# STM32MP13xx register map
File version: 1.5
CPU: CA7 r0p0, little endian, MPU, FPU, 4 interrupt priority bits
Registers are 32-bit, read-write, reset 0x0 unless marked. A register's access mark holds for its fields unless they carry their own. Offsets are from the block's base; [hi:lo] are bit positions; {n}, {i} and the like mark numbered series; 'fields as' and 'values as' point back to an identical list.

## RCC (part 6 of 7)
Base 0x50000000
0x790 RCC_MP_NS_AHB6ENSETR — This is a non-secure register for enabling the clock of the MDMA when it is used as non- secure. This register is used to set the peripheral clock enable bit of the corresponding peripheral. It shall be used to allocate a peripheral. Writing '0' has no effect, reading will return the effective values of the corresponding bits. Writing a '1' sets the corresponding bit to '1'.
  [0] MDMAEN — MDMA peripheral clocks enable Set by software.
    0=Writing '0' has no effect, reading '0' means that the peripheral clocks are disabled; 1=Writing '1' enables the peripheral clocks, reading '1' means that the peripheral clocks are enabled
0x794 RCC_MP_NS_AHB6ENCLRR — This is a non-secure register for disabling the clock of the MDMA when it is not used as non- secure. This register is used to clear the peripheral clock enable bit of the corresponding peripheral. It shall be used to deallocate a peripheral. Writing '0' has no effect, reading will return the effective values of the corresponding bits. Writing a '1' sets the corresponding bit to '0'.
  fields as RCC_MP_NS_AHB6ENSETR
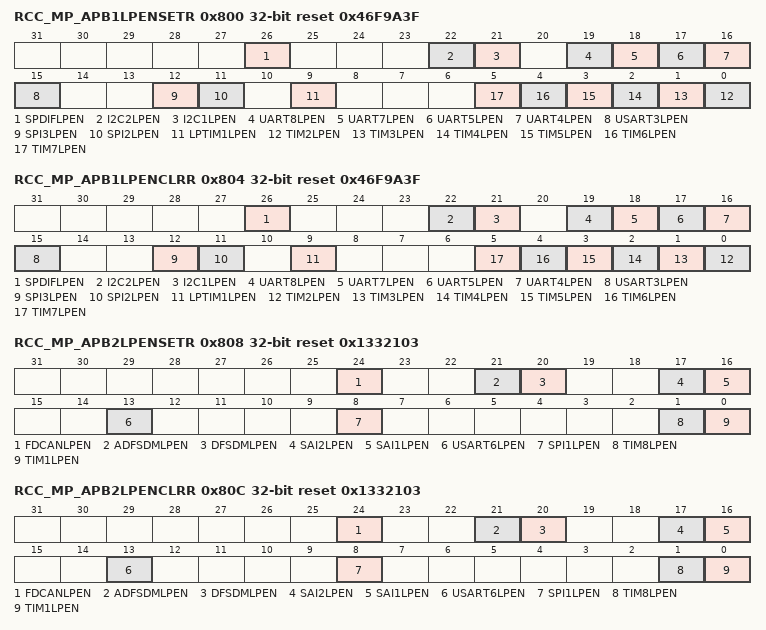
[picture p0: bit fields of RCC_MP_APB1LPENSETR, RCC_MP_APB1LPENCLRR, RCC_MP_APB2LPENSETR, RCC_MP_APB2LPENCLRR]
0x800 RCC_MP_APB1LPENSETR reset 0x46F9A3F — This register is used in order to set the PERxLPEN bit of the corresponding peripheral. Writing '0' has no effect, reading will return the effective values of the corresponding bits. Writing a '1' sets the corresponding bit to '1'.
  [all] fields
    0=Writing '0' has no effect, reading '0' means that the peripheral clocks are disabled in CSleep; 1=Writing '1' enables the peripheral clocks in CSleep, reading '1' means that the peripheral clocks are enabled in CSleep
  [26] SPDIFLPEN — SPDIFRX peripheral clocks enable during CSleep mode Set by software.
  [22] I2C2LPEN — I2C2 peripheral clocks enable during CSleep mode Set by software.
  [21] I2C1LPEN — I2C1 peripheral clocks enable during CSleep mode Set by software.
  [19] UART8LPEN — UART8 peripheral clocks enable during CSleep mode Set by software.
  [18] UART7LPEN — UART7 peripheral clocks enable during CSleep mode Set by software.
  [17] UART5LPEN — UART5 peripheral clocks enable during CSleep mode Set by software.
  [16] UART4LPEN — UART4 peripheral clocks enable during CSleep mode Set by software.
  [15] USART3LPEN — USART3 peripheral clocks enable during CSleep mode Set by software.
  [12] SPI3LPEN — SPI3 peripheral clocks enable during CSleep mode Set by software.
  [11] SPI2LPEN — SPI2 peripheral clocks enable during CSleep mode Set by software.
  [9] LPTIM1LPEN — LPTIM1 peripheral clocks enable during CSleep mode Set by software.
  [n-2] TIM{n}LPEN (n=2..7) — TIM{n} peripheral clocks enable during CSleep mode Set by software.
0x804 RCC_MP_APB1LPENCLRR reset 0x46F9A3F — This register is used in order to clear the PERxLPEN bit of the corresponding peripheral. Writing '0' has no effect, reading will return the effective values of the corresponding bits. Writing a '1' sets the corresponding bit to '0'.
  [all] fields
    0=Writing '0' has no effect, reading '0' means that the peripheral clocks are disabled in CSleep; 1=Writing '1' disables the peripheral clocks in CSleep, reading '1' means that the peripheral clocks are enabled in CSleep
  [26] SPDIFLPEN — SPDIFRX peripheral clocks enable during CSleep mode Cleared by software.
  [22] I2C2LPEN — I2C2 peripheral clocks enable during CSleep mode Cleared by software.
  [21] I2C1LPEN — I2C1 peripheral clocks enable during CSleep mode Cleared by software.
  [19] UART8LPEN — UART8 peripheral clocks enable during CSleep mode Cleared by software.
  [18] UART7LPEN — UART7 peripheral clocks enable during CSleep mode Cleared by software.
  [17] UART5LPEN — UART5 peripheral clocks enable during CSleep mode Cleared by software.
  [16] UART4LPEN — UART4 peripheral clocks enable during CSleep mode Cleared by software.
  [15] USART3LPEN — USART3 peripheral clocks enable during CSleep mode Cleared by software.
  [12] SPI3LPEN — SPI3 peripheral clocks enable during CSleep mode Cleared by software.
  [11] SPI2LPEN — SPI2 peripheral clocks enable during CSleep mode Cleared by software.
  [9] LPTIM1LPEN — LPTIM1 peripheral clocks enable during CSleep mode Cleared by software.
  [n-2] TIM{n}LPEN (n=2..7) — TIM{n} peripheral clocks enable during CSleep mode Cleared by software.
0x808 RCC_MP_APB2LPENSETR reset 0x1332103 — This register is used in order to set the PERxLPEN bit of the corresponding peripheral. Writing '0' has no effect, reading will return the effective values of the corresponding bits. Writing a '1' sets the corresponding bit to '1'.
  [all] fields
    values as the fields of RCC_MP_APB1LPENSETR
  [24] FDCANLPEN — FDCAN and CANRAM peripheral clocks enable during CSleep mode Set by software.
  [21] ADFSDMLPEN — Audio DFSDM peripheral clocks enable during CSleep mode Set by software.
  [20] DFSDMLPEN — DFSDM peripheral clocks enable during CSleep mode Set by software.
  [17] SAI2LPEN — SAI2 peripheral clocks enable during CSleep mode Set by software.
  [16] SAI1LPEN — SAI1 peripheral clocks enable during CSleep mode Set by software.
  [13] USART6LPEN — USART6 peripheral clocks enable during CSleep mode Set by software.
  [8] SPI1LPEN — SPI/I2S1 peripheral clocks enable during CSleep mode Set by software.
  [1] TIM8LPEN — TIM8 peripheral clocks enable during CSleep mode Set by software.
  [0] TIM1LPEN — TIM1 peripheral clocks enable during CSleep mode Set by software.
0x80C RCC_MP_APB2LPENCLRR reset 0x1332103 — This register is used in order to clear the PERxLPEN bit of the corresponding peripheral. Writing '0' has no effect, reading will return the effective values of the corresponding bits. Writing a '1' sets the corresponding bit to '0'.
  [all] fields
    values as the fields of RCC_MP_APB1LPENCLRR
  [24] FDCANLPEN — FDCAN and CANRAM peripheral clocks enable during CSleep mode Cleared by software.
  [21] ADFSDMLPEN — Audio DFSDM peripheral clocks enable during CSleep mode Cleared by software.
  [20] DFSDMLPEN — DFSDM peripheral clocks enable during CSleep mode Cleared by software.
  [17] SAI2LPEN — SAI2 peripheral clocks enable during CSleep mode Cleared by software.
  [16] SAI1LPEN — SAI1 peripheral clocks enable during CSleep mode Cleared by software.
  [13] USART6LPEN — USART6 peripheral clocks enable during CSleep mode Cleared by software.
  [8] SPI1LPEN — SPI/I2S1 peripheral clocks enable during CSleep mode Cleared by software.
  [1] TIM8LPEN — TIM8 peripheral clocks enable during CSleep mode Cleared by software.
  [0] TIM1LPEN — TIM1 peripheral clocks enable during CSleep mode Cleared by software.
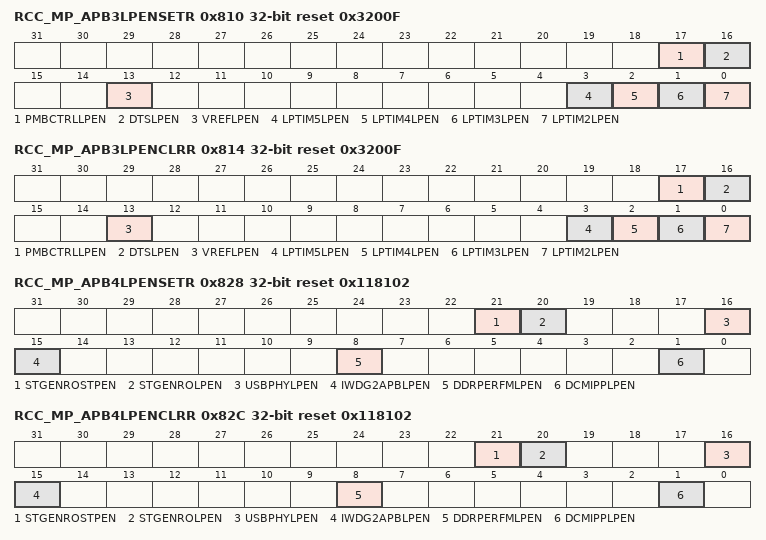
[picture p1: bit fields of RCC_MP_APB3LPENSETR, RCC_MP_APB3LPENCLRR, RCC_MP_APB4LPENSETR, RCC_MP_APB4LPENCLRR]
0x810 RCC_MP_APB3LPENSETR reset 0x3200F — This register may be separately and securely write-protected at a field level, as detailed in the following register fields description. This register is used in order to set the PERxLPEN bit of the corresponding peripheral. Writing '0' has no effect, reading will return the effective values of the corresponding bits. Writing a '1' sets the corresponding bit to '1'.
  [17] PMBCTRLLPEN — PMBCTRL peripheral clocks enable during CSeep mode (non-user): this bit is present in the RTL and is internally used as: SPIRIT parameter RTLPRESENT
  [16] DTSLPEN — DTS peripheral clocks enable during CSleep mode Set by software.
    values as the fields of RCC_MP_APB1LPENSETR
  [13] VREFLPEN — VREF peripheral clocks enable during CSleep mode If VREF block is configured as secure via the corresponding DECPROT[1] field of the ETZPC register, a write access to this register field must be secure. A read access may be secure or non-secure. Set by software.
    values as the fields of RCC_MP_APB1LPENSETR
  [3] LPTIM5LPEN — LPTIM5 peripheral clocks enable during CSleep mode Set by software.
    values as the fields of RCC_MP_APB1LPENSETR
  [2] LPTIM4LPEN — LPTIM4 peripheral clocks enable during CSleep mode Set by software.
    values as the fields of RCC_MP_APB1LPENSETR
  [1] LPTIM3LPEN — LPTIM3 peripheral clocks enable during CSleep mode If LPTIM3 block is configured as secure via the corresponding DECPROT[1] field of the ETZPC register, a write access to this register field must be secure. A read access may be secure or non-secure. Set by software.
    values as the fields of RCC_MP_APB1LPENSETR
  [0] LPTIM2LPEN — LPTIM2 peripheral clocks enable during CSleep mode If LPTIM2 block is configured as secure via the corresponding DECPROT[1] field of the ETZPC register, a write access to this register field must be secure. A read access may be secure or non-secure. Set by software.
    values as the fields of RCC_MP_APB1LPENSETR
0x814 RCC_MP_APB3LPENCLRR reset 0x3200F — This register may be separately and securely write-protected at a field level, as detailed in the following register fields description. This register is used in order to clear the PERxLPEN bit of the corresponding peripheral. Writing '0' has no effect, reading will return the effective values of the corresponding bits. Writing a '1' sets the corresponding bit to '0'.
  [17] PMBCTRLLPEN — PMBCTRL peripheral clocks enable during CSeep mode (non-user): this bit is present in the RTL and is internally used as: SPIRIT parameter RTLPRESENT
  [16] DTSLPEN — DTS peripheral clocks enable during CSleep mode Cleared by software.
    values as the fields of RCC_MP_APB1LPENCLRR
  [13] VREFLPEN — VREF peripheral clocks enable during CSleep mode If VREF block is configured as secure via the corresponding DECPROT[1] field of the ETZPC register, a write access to this register field must be secure. A read access may be secure or non-secure. Cleared by software.
    values as the fields of RCC_MP_APB1LPENCLRR
  [3] LPTIM5LPEN — LPTIM5 peripheral clocks enable during CSleep mode Cleared by software.
    values as the fields of RCC_MP_APB1LPENCLRR
  [2] LPTIM4LPEN — LPTIM4 peripheral clocks enable during CSleep mode Cleared by software.
    values as the fields of RCC_MP_APB1LPENCLRR
  [1] LPTIM3LPEN — LPTIM3 peripheral clocks enable during CSleep mode If LPTIM3 block is configured as secure via the corresponding DECPROT[1] field of the ETZPC register, a write access to this register field must be secure. A read access may be secure or non-secure. Cleared by software.
    values as the fields of RCC_MP_APB1LPENCLRR
  [0] LPTIM2LPEN — LPTIM2 peripheral clocks enable during CSleep mode If LPTIM2 block is configured as secure via the corresponding DECPROT[1] field of the ETZPC register, a write access to this register field must be secure. A read access may be secure or non-secure. Cleared by software.
    values as the fields of RCC_MP_APB1LPENCLRR
0x818 RCC_MP_S_APB3LPENSETR reset 0x1 — This is a secure register for enabling the clock of the SYSCFG. A write access to this register field must be secure. A read access may be secure or non-secure. This register is used in order to set the PERxLPEN bit of the corresponding peripheral. Writing '0' has no effect, reading will return the effective values of the corresponding bits. Writing a '1' sets the corresponding bit to '1'.
  [0] SYSCFGLPEN — SYSCFG peripheral clocks enable during CSleep mode Set by (secure) software.
    values as the fields of RCC_MP_APB1LPENSETR
0x81C RCC_MP_S_APB3LPENCLRR reset 0x1 — This is a secure register for disabling the clock of the SYSCFG. A write access to this register field must be secure. A read access may be secure or non-secure. This register is used in order to clear the PERxLPEN bit of the corresponding peripheral. Writing '0' has no effect, reading will return the effective values of the corresponding bits. Writing a '1' sets the corresponding bit to '0'.
  [0] SYSCFGLPEN — SYSCFG peripheral clocks enable during CSleep mode Cleared by (secure) software.
    values as the fields of RCC_MP_APB1LPENCLRR
0x820 RCC_MP_NS_APB3LPENSETR reset 0x1 — This is a non-secure register, for enabling the clock of the SYSCFG. This register is used in order to set the PERxLPEN bit of the corresponding peripheral. Writing '0' has no effect, reading will return the effective values of the corresponding bits. Writing a '1' sets the corresponding bit to '1'.
  [0] SYSCFGLPEN — SYSCFG peripheral clocks enable during CSleep mode Set by software.
    values as the fields of RCC_MP_APB1LPENSETR
0x824 RCC_MP_NS_APB3LPENCLRR reset 0x1 — This is a non-secure register, for disabling the clock of the SYSCFG. This register is used in order to clear the PERxLPEN bit of the corresponding peripheral. Writing '0' has no effect, reading will return the effective values of the corresponding bits. Writing a '1' sets the corresponding bit to '0'.
  [0] SYSCFGLPEN — SYSCFG peripheral clocks enable during CSleep mode Cleared by software.
    values as the fields of RCC_MP_APB1LPENCLRR
0x828 RCC_MP_APB4LPENSETR reset 0x118102 — This register may be separately and securely write-protected at a field level, as detailed in the following register fields description. This register is used in order to set the PERxLPEN bit of the corresponding peripheral. Writing '0' has no effect, reading will return the effective values of the corresponding bits. Writing a '1' sets the corresponding bit to '1'.
  [21] STGENROSTPEN — STGEN read-only interface peripheral clocks enable during CStop mode Set by software. The peripheral clocks of the STGEN read-only interface are the pclk4, and the kernel clock as selected by the RCC_STGENCKSELR register.
    0=Writing '0' has no effect, reading '0' means that the pclk4 is disabled in CStop, and that the kernel clock gating is defined by RCC_MP_APB5ENxxxR.STGENCEN with xxx=SET/CLR; 1=Writing '1' enables the pclk4 and the kernel clock in CStop; reading '1' means that the pck4 and the kernel clock are enabled in CStop
  [20] STGENROLPEN — STGEN read-only interface peripheral clocks enable during CSleep mode Set by software. The peripheral clocks of the STGEN read-only interface are the pclk4, and the kernel clock as selected by the RCC_STGENCKSELR register.
    0=Writing '0' has no effect, reading '0' means that the pclk4 is disabled in CSleep, and that the kernel clock gating is defined by RCC_MP_APB5ENxxxR.STGENCEN with xxx=SET/CLR; 1=Writing '1' enables the pclk4 and the kernel clock in CSleep; reading '1' means that the pck4 and the kernel clock are enabled in CSleep
  [16] USBPHYLPEN — USBPHYC peripheral clocks enable during CSleep mode If USB PHY is configured as secure via the corresponding DECPROT[1] field of the ETZPC register, a write access to this register field must be secure. A read access may be secure or non-secure. Set by software.
    values as the fields of RCC_MP_APB1LPENSETR
  [15] IWDG2APBLPEN — IWDG2 APB clock enable during CSleep mode Set by software.
    0=Writing '0' has no effect, reading '0' means that the APB clock is disabled in CSleep; 1=Writing '1' enables the APB clock in CSleep, reading '1' means that the APB clock is enabled in CSleep
  [8] DDRPERFMLPEN — DDRPERFM APB clock enable during CSleep mode Set by software.
    values as IWDG2APBLPEN
  [1] DCMIPPLPEN — DCMIPP peripheral clocks enable during CSleep mode If DCMIPP is configured as secure via the corresponding DECPROT[1] field of the ETZPC register, a write access to this register field must be secure. A read access may be secure or non-secure. Set by software.
    values as the fields of RCC_MP_APB1LPENSETR
0x82C RCC_MP_APB4LPENCLRR reset 0x118102 — This register may be separately and securely write-protected at a field level, as detailed in the following register fields description. This register is used in order to clear the PERxLPEN bit of the corresponding peripheral. Writing '0' has no effect, reading will return the effective values of the corresponding bits. Writing a '1' sets the corresponding bit to '0'.
  [21] STGENROSTPEN — STGEN read-only interface peripheral clocks enable during CStop mode Cleared by software. The peripheral clocks of the STGEN read-only interface are the pclk4, and the kernel clock as selected by the RCC_STGENCKSELR register.
    0=Writing '0' has no effect, reading '0' means that the pclk4 is disabled in CStop, and that the kernel clock gating is defined by RCC_MP_APB5LPENxxxR.STGENCLPEN with xxx=SET/CLR; 1=Writing '1' disables the pclk4 and the kernel clock in CStop; reading '1' means that the pck4 and the kernel clock are enabled in CStop
  [20] STGENROLPEN — STGEN read-only interface peripheral clocks enable during CSleep mode Cleared by software. The peripheral clocks of the STGEN read-only interface are the pclk4, and the kernel clock as selected by the RCC_STGENCKSELR register.
    0=Writing '0' has no effect, reading '0' means that the pclk4 is disabled in CSleep, and that the kernel clock gating is defined by RCC_MP_APB5LPENxxxR.STGENCLPEN with xxx=SET/CLR; 1=Writing '1' disables the pclk4 and the kernel clock in CSleep; reading '1' means that the pck4 and the kernel clock are enabled in CSleep
  [16] USBPHYLPEN — USBPHYC peripheral clocks enable during CSleep mode If USB PHY is configured as secure via the corresponding DECPROT[1] field of the ETZPC register, a write access to this register field must be secure. A read access may be secure or non-secure. Cleared by software.
    values as the fields of RCC_MP_APB1LPENCLRR
  [15] IWDG2APBLPEN — IWDG2 APB clock enable during CSleep mode Cleared by software.
    0=Writing '0' has no effect, reading '0' means that the APB clock is disabled in CSleep; 1=Writing '1' disables the APB clock in CSleep, reading '1' means that the APB clock is enabled in CSleep
  [8] DDRPERFMLPEN — DDRPERFM APB clock enable during CSleep mode Cleared by software.
    values as IWDG2APBLPEN
  [1] DCMIPPLPEN — DCMIPP peripheral clocks enable during CSleep mode If DCMIPP is configured as secure via the corresponding DECPROT[1] field of the ETZPC register, a write access to this register field must be secure. A read access may be secure or non-secure. Cleared by software.
    values as the fields of RCC_MP_APB1LPENCLRR
0x830 RCC_MP_S_APB4LPENSETR reset 0x1 — This is a secure register for enabling the clock of the LTDC when it is used with a secure composition layer. A write access to this register field must be secure. A read access may be secure or non-secure. This register is used in order to set the PERxLPEN bit of the corresponding peripheral. Writing '0' has no effect, reading will return the effective values of the corresponding bits. Writing a '1' sets the corresponding bit to '1'.
  [0] LTDCLPEN — LTDC peripheral clocks enable during CSleep mode Set by (secure) software.
    0=Writing '0' has no effect, reading '0' means that the peripheral clocks are disabled in CSleep; 1=Writing '1' enables the peripheral clocks in CSleep, reading '1' means that the peripheral clocks are enabled
0x834 RCC_MP_S_APB4LPENCLRR reset 0x1 — This is a secure register for disabling the clock of the LTDC when it is used with a secure composition layer. A write access to this register field must be secure. A read access may be secure or non-secure. This register is used in order to clear the PERxLPEN bit of the corresponding peripheral. Writing '0' has no effect, reading will return the effective values of the corresponding bits. Writing a '1' sets the corresponding bit to '0'.
  [0] LTDCLPEN — LTDC peripheral clocks enable during CSleep mode Cleared by (secure) software.
    0=Writing '0' has no effect, reading '0' means that the peripheral clocks are disabled in CSleep; 1=Writing '1' disables the peripheral clocks in CSleep, reading '1' means that the peripheral clocks are enabled
0x838 RCC_MP_NS_APB4LPENSETR reset 0x1 — This is a non-secure register, for enabling the clock of the LTDC when it is used with one or two non-secure composition layers. This register is used in order to set the PERxLPEN bit of the corresponding peripheral. Writing '0' has no effect, reading will return the effective values of the corresponding bits. Writing a '1' sets the corresponding bit to '1'.
  [0] LTDCLPEN — LTDC peripheral clocks enable during CSleep mode Set by software.
    values as RCC_MP_S_APB4LPENSETR.LTDCLPEN
0x83C RCC_MP_NS_APB4LPENCLRR reset 0x1 — This is a non-secure register, for disabling the clock of the LTDC when it is used with one or two non-secure composition layers. This register is used in order to clear the PERxLPEN bit of the corresponding peripheral. Writing '0' has no effect, reading will return the effective values of the corresponding bits. Writing a '1' sets the corresponding bit to '0'.
  [0] LTDCLPEN — LTDC peripheral clocks enable during CSleep mode Cleared by software.
    values as RCC_MP_S_APB4LPENCLRR.LTDCLPEN
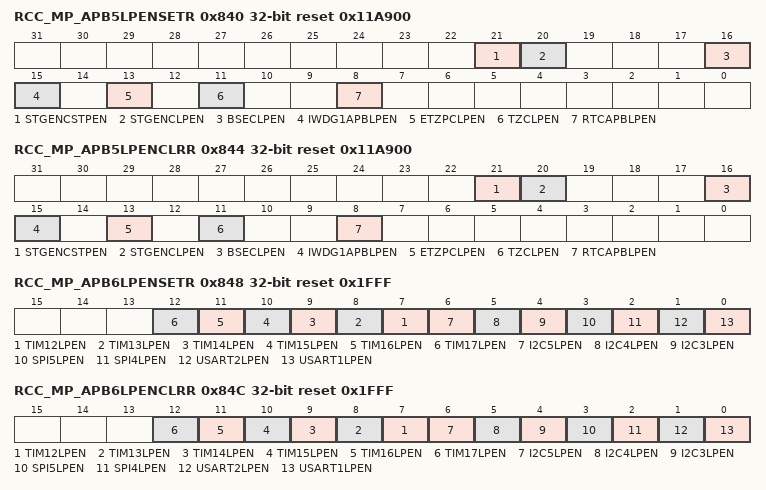
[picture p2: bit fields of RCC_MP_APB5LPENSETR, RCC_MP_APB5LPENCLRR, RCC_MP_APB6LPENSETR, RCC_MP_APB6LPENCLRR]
0x840 RCC_MP_APB5LPENSETR reset 0x11A900 — This register may be separately and securely write-protected at a field level, as detailed in the following register fields description. This register is used in order to set the PERxLPEN bit of the corresponding peripheral. Writing '0' has no effect, reading will return the effective values of the corresponding bits. Writing a '1' sets the corresponding bit to '1'.
  [21] STGENCSTPEN — STGEN controller part, peripheral clocks enable during CStop mode If STGENC is configured as secure via the corresponding DECPROT[1] field of the ETZPC register, a write access to this register field must be secure. A read access may be secure or non-secure. Set by software. The peripheral clocks of the STGEN controller part are the pclk5, and the kernel clock as selected by the RCC_STGENCKSELR register.
    0=Writing '0' has no effect, reading '0' means that the pclk5 is disabled in CStop, and that the kernel clock gating is defined by RCC_MP_APB4ENxxxR.STGENROSTPEN with xxx=SET/CLR; 1=Writing '1' enables the pclk5 and the kernel clock in CStop; reading '1' means that the pck5 and the kernel clock are enabled in CStop
  [20] STGENCLPEN — STGEN controller part, peripheral clocks enable during CSleep mode If STGENC is configured as secure via the corresponding DECPROT[1] field of the ETZPC register, a write access to this register field must be secure. A read access may be secure or non-secure. Set by software. The peripheral clocks of the STGEN controller part are the pclk5, and the kernel clock as selected by the RCC_STGENCKSELR register.
    0=Writing '0' has no effect, reading '0' means that the pclk5 is disabled in CSleep, and that the kernel clock gating is defined by RCC_MP_APB4ENxxxR.STGENROLPEN with xxx=SET/CLR; 1=Writing '1' enables the pclk5 and the kernel clock in CSleep; reading '1' means that the pck5 and the kernel clock are enabled in CSleep
  [16] BSECLPEN — BSEC peripheral clocks enable during CSleep mode A write access to this register field must be secure. A read access may be secure or non-secure. Set by (secure) software.
    values as the fields of RCC_MP_APB1LPENSETR
  [15] IWDG1APBLPEN — IWDG1 APB clock enable during CSleep mode If IWDG1 is configured as secure via the corresponding DECPROT[1] field of the ETZPC register, a write access to this register field must be secure. A read access may be secure or non-secure. Set by software.
    values as RCC_MP_APB4LPENSETR.IWDG2APBLPEN
  [13] ETZPCLPEN — ETZPC peripheral clocks enable during CSleep mode A write access to this register field must be secure. A read access may be secure or non-secure. Set by (secure) software.
    values as the fields of RCC_MP_APB1LPENSETR
  [11] TZCLPEN — TZC clocks enable during CSleep mode Set by (secure) software. See for details.
    0=Writing '0' has no effect, reading '0' means that the peripheral clocks are disabled in CSleep; 1=Writing '1' enables the pclk5 and aclk_tzc1 clocks in CSleep, reading '1' means that the clocks are enabled in CSleep
  [8] RTCAPBLPEN — RTC APB clock enable during CSleep mode If at least one function of the RTC is configured as secure via the RTC_SECCFGR register (i.e. if the input signal rtc_sec driven by RTC is asserted), a write access to this register field must be secure. A read access may be secure or non-secure. Set by software.
    values as the fields of RCC_MP_APB1LPENSETR
0x844 RCC_MP_APB5LPENCLRR reset 0x11A900 — This register may be separately and securely write-protected at a field level, as detailed in the following register fields description. This register is used in order to clear the PERxLPEN bit of the corresponding peripheral. Writing '0' has no effect, reading will return the effective values of the corresponding bits. Writing a '1' sets the corresponding bit to '0'.
  [21] STGENCSTPEN — STGEN controller part, peripheral clocks enable during CStop mode If STGENC is configured as secure via the corresponding DECPROT[1] field of the ETZPC register, a write access to this register field must be secure. A read access may be secure or non-secure. Cleared by software. The peripheral clocks of the STGEN controller part are the pclk5, and the kernel clock as selected by the RCC_STGENCKSELR register.
    0=Writing '0' has no effect, reading '0' means that the pclk5 is disabled in CStop, and that the kernel clock gating is defined by RCC_MP_APB4LPENxxxR.STGENROSTPEN with xxx=SET/CLR; 1=Writing '1' disables the pclk5 and the kernel clock in CStop; reading '1' means that the pck5 and the kernel clock are enabled in CStop
  [20] STGENCLPEN — STGEN controller part, peripheral clocks enable during CSleep mode If STGENC is configured as secure via the corresponding DECPROT[1] field of the ETZPC register, a write access to this register field must be secure. A read access may be secure or non-secure. Cleared by software. The peripheral clocks of the STGEN controller part are the pclk5, and the kernel clock as selected by the RCC_STGENCKSELR register.
    0=Writing '0' has no effect, reading '0' means that the pclk5 is disabled in CSleep, and that the kernel clock gating is defined by RCC_MP_APB4LPENxxxR.STGENROLPEN with xxx=SET/CLR; 1=Writing '1' disables the pclk5 and the kernel clock in CSleep; reading '1' means that the pck5 and the kernel clock are enabled in CSleep
  [16] BSECLPEN — BSEC peripheral clocks enable during CSleep mode A write access to this register field must be secure. A read access may be secure or non-secure. Cleared by (secure) software.
    values as the fields of RCC_MP_APB1LPENCLRR
  [15] IWDG1APBLPEN — IWDG1 APB clock enable during CSleep mode If IWDG1 is configured as secure via the corresponding DECPROT[1] field of the ETZPC register, a write access to this register field must be secure. A read access may be secure or non-secure. Cleared by software.
    values as RCC_MP_APB4LPENCLRR.IWDG2APBLPEN
  [13] ETZPCLPEN — ETZPC peripheral clocks enable during CSleep mode A write access to this register field must be secure. A read access may be secure or non-secure. Cleared by (secure) software.
    values as the fields of RCC_MP_APB1LPENCLRR
  [11] TZCLPEN — TZC clocks enable during CSleep mode Cleared by (secure) software. See for details.
    0=Writing '0' has no effect, reading '0' means that the peripheral clocks are disabled in CSleep; 1=Writing '1' disables the pclk5 and aclk_tzc1 clocks in CSleep, reading '1' means that the clocks are enabled in CSleep
  [8] RTCAPBLPEN — RTC APB clock enable during CSleep mode If at least one function of the RTC is configured as secure via the RTC_SECCFGR register (i.e. if the input signal rtc_sec driven by RTC is asserted), a write access to this register field must be secure. A read access may be secure or non-secure. Cleared by software.
    values as the fields of RCC_MP_APB1LPENCLRR
0x848 RCC_MP_APB6LPENSETR reset 0x1FFF — This register may be separately and securely write-protected at a field level depending on the secure state of the corresponding peripheral, i.e. depending on the corresponding DECPROT[1] field of the ETZPC register. This register is used in order to set the PERxLPEN bit of the corresponding peripheral. Writing '0' has no effect, reading will return the effective values of the corresponding bits. Writing a '1' sets the corresponding bit to '1'.
  [all] fields
    0=Writing '0' has no effect, reading '0' means that the peripherals clocks are disabled in CSleep; 1=Writing '1' enables the peripherals clocks in CSleep, reading '1' means that the peripherals clocks are enabled in CSleep
  [n-5] TIM{n}LPEN (n=12..17) — TIM{n} peripherals clocks during CSleep mode If TIM{n} is configured as secure via the corresponding DECPROT[1] field of the ETZPC register, a write access to this register field must be secure. A read access may be secure or non-secure. Cleared by software.
  [6] I2C5LPEN — I2C5 peripherals clocks during CSleep mode If I2C5 is configured as secure via the corresponding DECPROT[1] field of the ETZPC register, a write access to this register field must be secure. A read access may be secure or non-secure. Cleared by software.
  [5] I2C4LPEN — I2C4 peripherals clocks during CSleep mode If I2C4 is configured as secure via the corresponding DECPROT[1] field of the ETZPC register, a write access to this register field must be secure. A read access may be secure or non-secure. Cleared by software.
  [4] I2C3LPEN — I2C3 peripherals clocks during CSleep mode If I2C3 is configured as secure via the corresponding DECPROT[1] field of the ETZPC register, a write access to this register field must be secure. A read access may be secure or non-secure. Cleared by software.
  [3] SPI5LPEN — SPI5 peripherals clocks during CSleep mode If SPI5 is configured as secure via the corresponding DECPROT[1] field of the ETZPC register, a write access to this register field must be secure. A read access may be secure or non-secure. Cleared by software.
  [2] SPI4LPEN — SPI4 peripherals clocks during CSleep mode If SPI4 is configured as secure via the corresponding DECPROT[1] field of the ETZPC register, a write access to this register field must be secure. A read access may be secure or non-secure. Cleared by software.
  [1] USART2LPEN — USART2 peripherals clocks during CSleep mode If USART2 is configured as secure via the corresponding DECPROT[1] field of the ETZPC register, a write access to this register field must be secure. A read access may be secure or non-secure. Cleared by software.
  [0] USART1LPEN — USART1 peripherals clocks during CSleep mode If USART1 is configured as secure via the corresponding DECPROT[1] field of the ETZPC register, a write access to this register field must be secure. A read access may be secure or non-secure. Cleared by software.
0x84C RCC_MP_APB6LPENCLRR reset 0x1FFF — This register may be separately and securely write-protected at a field level depending on the secure state of the corresponding peripheral, i.e. depending on the corresponding DECPROT[1] field of the ETZPC register. This register is used in order to clear the PERxLPEN bit of the corresponding peripheral. Writing '0' has no effect, reading will return the effective values of the corresponding bits. Writing a '1' sets the corresponding bit to '0'.
  [all] fields
    0=Writing '0' has no effect, reading '0' means that the peripherals clocks are disabled in CSleep; 1=Writing '1' disables the peripherals clocks in CSleep, reading '1' means that the peripherals clocks are enabled in CSleep
  [n-5] TIM{n}LPEN (n=12..17) — TIM{n} peripherals clocks during CSleep mode If TIM{n} is configured as secure via the corresponding DECPROT[1] field of the ETZPC register, a write access to this register field must be secure. A read access may be secure or non-secure. Set by software.
  [6] I2C5LPEN — I2C5 peripherals clocks during CSleep mode If I2C5 is configured as secure via the corresponding DECPROT[1] field of the ETZPC register, a write access to this register field must be secure. A read access may be secure or non-secure. Set by software.
  [5] I2C4LPEN — I2C4 peripherals clocks during CSleep mode If I2C4 is configured as secure via the corresponding DECPROT[1] field of the ETZPC register, a write access to this register field must be secure. A read access may be secure or non-secure. Set by software.
  [4] I2C3LPEN — I2C3 peripherals clocks during CSleep mode If I2C3 is configured as secure via the corresponding DECPROT[1] field of the ETZPC register, a write access to this register field must be secure. A read access may be secure or non-secure. Set by software.
  [3] SPI5LPEN — SPI5 peripherals clocks during CSleep mode If SPI5 is configured as secure via the corresponding DECPROT[1] field of the ETZPC register, a write access to this register field must be secure. A read access may be secure or non-secure. Set by software.
  [2] SPI4LPEN — SPI4 peripherals clocks during CSleep mode If SPI4 is configured as secure via the corresponding DECPROT[1] field of the ETZPC register, a write access to this register field must be secure. A read access may be secure or non-secure. Set by software.
  [1] USART2LPEN — USART2 peripherals clocks during CSleep mode If USART2 is configured as secure via the corresponding DECPROT[1] field of the ETZPC register, a write access to this register field must be secure. A read access may be secure or non-secure. Set by software.
  [0] USART1LPEN — USART1 peripherals clocks during CSleep mode If USART1 is configured as secure via the corresponding DECPROT[1] field of the ETZPC register, a write access to this register field must be secure. A read access may be secure or non-secure. Set by software.
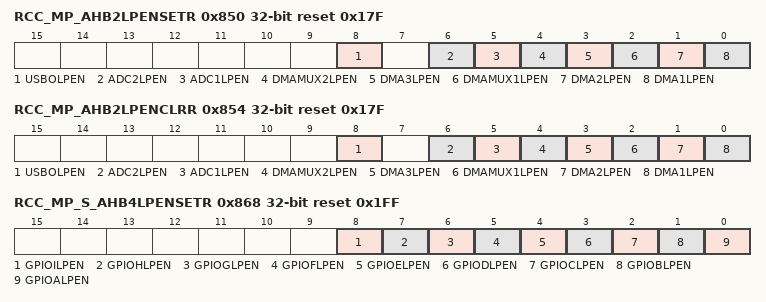
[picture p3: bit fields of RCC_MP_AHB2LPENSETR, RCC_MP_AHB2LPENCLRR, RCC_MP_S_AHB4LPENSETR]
0x850 RCC_MP_AHB2LPENSETR reset 0x17F — This register may be separately and securely write-protected at a field level depending on the secure state of the corresponding peripheral, i.e. depending on the corresponding DECPROT[1] field of the ETZPC register. This register is used in order to set the PERxLPEN bit of the corresponding peripheral. Writing '0' has no effect, reading will return the effective values of the corresponding bits. Writing a '1' sets the corresponding bit to '1'.
  [all] fields
    values as the fields of RCC_MP_APB1LPENSETR
  [8] USBOLPEN — USBO peripheral clocks enable during Sleep mode If USBO is configured as secure via the corresponding DECPROT[1] field of the ETZPC register, a write access to this register field must be secure. A read access may be secure or non-secure. Set by software.
  [6] ADC2LPEN — ADC2 peripheral clocks enable during Sleep mode If ADC2 is configured as secure via the corresponding DECPROT[1] field of the ETZPC register, a write access to this register field must be secure. A read access may be secure or non-secure. Set by software.
  [5] ADC1LPEN — ADC1 peripheral clocks enable during Sleep mode If ADC1 is configured as secure via the corresponding DECPROT[1] field of the ETZPC register, a write access to this register field must be secure. A read access may be secure or non-secure. Set by software.
  [4] DMAMUX2LPEN — DMAMUX2 peripheral clocks enable during Sleep mode If DMAMUX2 is configured as secure via the corresponding DECPROT[1] field of the ETZPC register, a write access to this register field must be secure. A read access may be secure or non-secure. Set by software.
  [3] DMA3LPEN — DMA3 peripheral clocks enable during Sleep mode If DMA3 is configured as secure via the corresponding DECPROT[1] field of the ETZPC register, a write access to this register field must be secure. A read access may be secure or non-secure. Set by software.
  [2] DMAMUX1LPEN — DMAMUX1 peripheral clocks enable during Sleep mode Set by software.
  [1] DMA2LPEN — DMA2 peripheral clocks enable during Sleep mode Set by software.
  [0] DMA1LPEN — DMA1 peripheral clocks enable during Sleep mode Set by software.
0x854 RCC_MP_AHB2LPENCLRR reset 0x17F — This register may be separately and securely write-protected at a field level depending on the secure state of the corresponding peripheral, i.e. depending on the corresponding DECPROT[1] field of the ETZPC register. This register is used in order to clear the PERxLPEN bit of the corresponding peripheral. Writing '0' has no effect, reading will return the effective values of the corresponding bits. Writing a '1' sets the corresponding bit to '0'.
  [all] fields
    values as the fields of RCC_MP_APB1LPENCLRR
  [8] USBOLPEN — USBO peripheral clocks enable during Sleep mode If USBO is configured as secure via the corresponding DECPROT[1] field of the ETZPC register, a write access to this register field must be secure. A read access may be secure or non-secure. Cleared by software.
  [6] ADC2LPEN — ADC2 peripheral clocks enable during Sleep mode If ADC2 is configured as secure via the corresponding DECPROT[1] field of the ETZPC register, a write access to this register field must be secure. A read access may be secure or non-secure. Cleared by software.
  [5] ADC1LPEN — ADC1 peripheral clocks enable during Sleep mode If ADC1 is configured as secure via the corresponding DECPROT[1] field of the ETZPC register, a write access to this register field must be secure. A read access may be secure or non-secure. Cleared by software.
  [4] DMAMUX2LPEN — DMAMUX2 peripheral clocks enable during Sleep mode If DMAMUX2 is configured as secure via the corresponding DECPROT[1] field of the ETZPC register, a write access to this register field must be secure. A read access may be secure or non-secure. Cleared by software.
  [3] DMA3LPEN — DMA3 peripheral clocks enable during Sleep mode If DMA3 is configured as secure via the corresponding DECPROT[1] field of the ETZPC register, a write access to this register field must be secure. A read access may be secure or non-secure. Cleared by software.
  [2] DMAMUX1LPEN — DMAMUX1 peripheral clocks enable during Sleep mode Cleared by software.
  [1] DMA2LPEN — DMA2 peripheral clocks enable during Sleep mode Cleared by software.
  [0] DMA1LPEN — DMA1 peripheral clocks enable during Sleep mode Cleared by software.
0x858 RCC_MP_AHB4LPENSETR reset 0x8000 — This register may be write-protected depending on the secure state of the TSC peripheral, i.e. depending on the corresponding DECPROT[1] field of the ETZPC register. This register is used in order to set the PERxLPEN bit of the corresponding peripheral. Writing '0' has no effect, reading will return the effective values of the corresponding bits. Writing a '1' sets the corresponding bit to '1'.
  [15] TSCLPEN — TSC peripheral clocks enable during CSleep mode Set by software.
    values as the fields of RCC_MP_APB1LPENSETR
0x85C RCC_MP_AHB4LPENCLRR reset 0x8000 — RCC AHB4 Sleep clock enable clear register
  [15] TSCLPEN — TSC peripheral clocks enable during CSleep mode Cleared by software.
    values as the fields of RCC_MP_APB1LPENCLRR
0x868 RCC_MP_S_AHB4LPENSETR reset 0x1FF — This is a secure register, for enabling the clock of the secure (AHB4) GPIO ports, as defined by the GPIO register file and more specifically the GPIOxSECCFGR.SECy control bit with x=A..I, and y = 0..15 (or 2 for x=I). A write access to this register field must be secure. A read access may be secure or non-secure. This register is used in order to set the PERxLPEN bit of the corresponding peripheral. Writing '0' has no effect, reading will return the effective values of the corresponding bits. Writing a '1' sets the corresponding bit to '1'.
  [all] fields
    values as the fields of RCC_MP_APB1LPENSETR
  [8] GPIOILPEN — GPIOI peripheral clocks enable during CSleep mode Set by (secure) software.
  [7] GPIOHLPEN — GPIOH peripheral clocks enable during CSleep mode Set by (secure) software.
  [6] GPIOGLPEN — GPIOG peripheral clocks enable during CSleep mode Set by (secure) software.
  [5] GPIOFLPEN — GPIOF peripheral clocks enable during CSleep mode Set by (secure) software.
  [4] GPIOELPEN — GPIOE peripheral clocks enable during CSleep mode Set by (secure) software.
  [3] GPIODLPEN — GPIOD peripheral clocks enable during CSleep mode Set by (secure) software.
  [2] GPIOCLPEN — GPIOC peripheral clocks enable during CSleep mode Set by (secure) software.
  [1] GPIOBLPEN — GPIOB peripheral clocks enable during CSleep mode Set by (secure) software.
  [0] GPIOALPEN — GPIOA peripheral clocks enable during CSleep mode Set by (secure) software.
